# iostr912f register map
Registers are 32-bit, access not given, no defined reset value unless marked. A register's access mark holds for its fields unless they carry their own. Addresses are absolute; registers are grouped by the start of their names; [hi:lo] are bit positions; 'fields as' and 'values as' point back to an identical list.

## SSP1
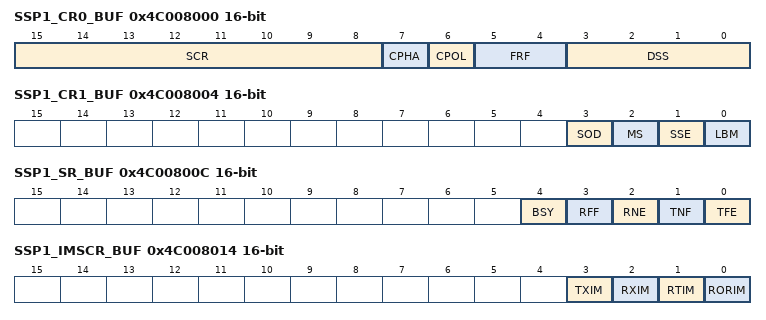
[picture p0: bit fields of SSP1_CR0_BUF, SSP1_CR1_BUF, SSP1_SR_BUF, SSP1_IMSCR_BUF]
0x4C008000 SSP1_CR0_BUF 16-bit
  [15:8] SCR, [7] CPHA, [6] CPOL, [5:4] FRF, [3:0] DSS
0x4C008004 SSP1_CR1_BUF 16-bit
  [3] SOD, [2] MS, [1] SSE, [0] LBM
0x4C008008 SSP1_DR_BUF 16-bit
0x4C00800C SSP1_SR_BUF 16-bit
  [4] BSY, [3] RFF, [2] RNE, [1] TNF, [0] TFE
0x4C008010 SSP1_PR_BUF 8-bit
0x4C008014 SSP1_IMSCR_BUF 16-bit
  [3] TXIM, [2] RXIM, [1] RTIM, [0] RORIM
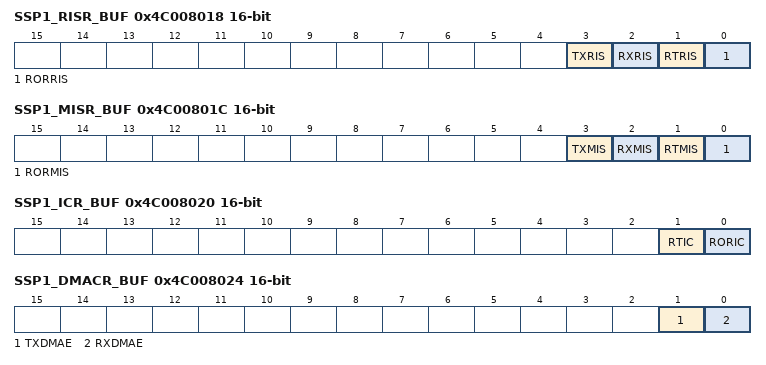
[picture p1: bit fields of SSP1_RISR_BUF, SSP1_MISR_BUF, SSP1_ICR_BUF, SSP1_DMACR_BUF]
0x4C008018 SSP1_RISR_BUF 16-bit
  [3] TXRIS, [2] RXRIS, [1] RTRIS, [0] RORRIS
0x4C00801C SSP1_MISR_BUF 16-bit
  [3] TXMIS, [2] RXMIS, [1] RTMIS, [0] RORMIS
0x4C008020 SSP1_ICR_BUF 16-bit
  [1] RTIC, [0] RORIC
0x4C008024 SSP1_DMACR_BUF 16-bit
  [1] TXDMAE, [0] RXDMAE
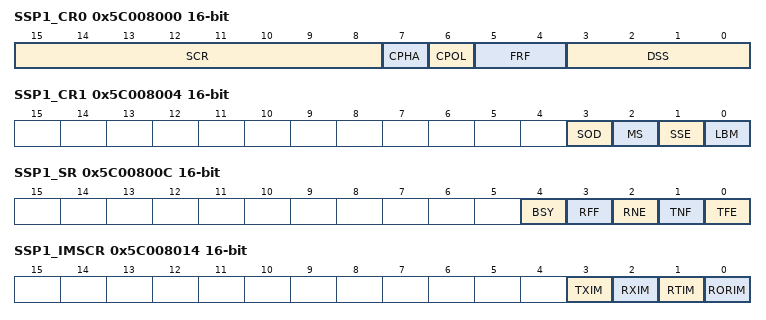
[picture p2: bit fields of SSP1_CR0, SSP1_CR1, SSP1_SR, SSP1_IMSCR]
0x5C008000 SSP1_CR0 16-bit
  [15:8] SCR, [7] CPHA, [6] CPOL, [5:4] FRF, [3:0] DSS
0x5C008004 SSP1_CR1 16-bit
  [3] SOD, [2] MS, [1] SSE, [0] LBM
0x5C008008 SSP1_DR 16-bit
0x5C00800C SSP1_SR 16-bit
  [4] BSY, [3] RFF, [2] RNE, [1] TNF, [0] TFE
0x5C008010 SSP1_PR 8-bit
0x5C008014 SSP1_IMSCR 16-bit
  [3] TXIM, [2] RXIM, [1] RTIM, [0] RORIM
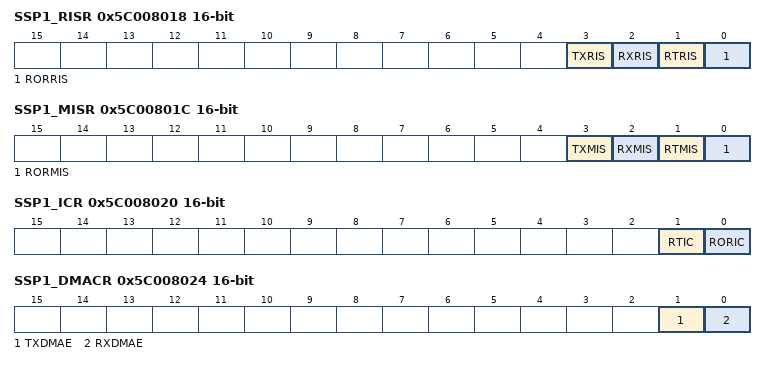
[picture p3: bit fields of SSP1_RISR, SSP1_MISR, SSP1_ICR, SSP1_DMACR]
0x5C008018 SSP1_RISR 16-bit
  [3] TXRIS, [2] RXRIS, [1] RTRIS, [0] RORRIS
0x5C00801C SSP1_MISR 16-bit
  [3] TXMIS, [2] RXMIS, [1] RTMIS, [0] RORMIS
0x5C008020 SSP1_ICR 16-bit
  [1] RTIC, [0] RORIC
0x5C008024 SSP1_DMACR 16-bit
  [1] TXDMAE, [0] RXDMAE

## UART0
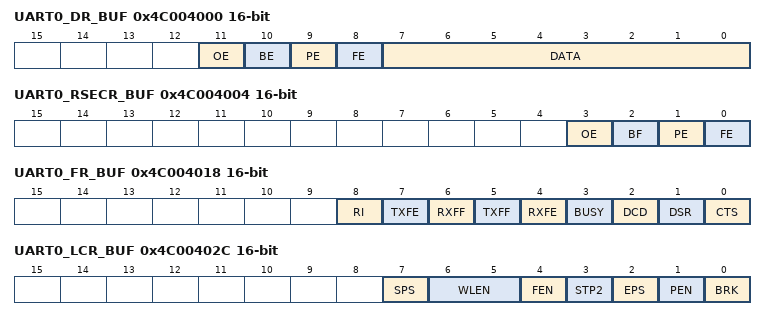
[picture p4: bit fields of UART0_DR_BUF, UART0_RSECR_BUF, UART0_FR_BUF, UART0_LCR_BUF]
0x4C004000 UART0_DR_BUF 16-bit
  [11] OE, [10] BE, [9] PE, [8] FE, [7:0] DATA
0x4C004004 UART0_RSECR_BUF 16-bit
  [3] OE, [2] BF, [1] PE, [0] FE
0x4C004018 UART0_FR_BUF 16-bit
  [8] RI, [7] TXFE, [6] RXFF, [5] TXFF, [4] RXFE, [3] BUSY, [2] DCD, [1] DSR, [0] CTS
0x4C004020 UART0_ILPR_BUF 8-bit
0x4C004024 UART0_IBRD_BUF 16-bit
0x4C004028 UART0_FBRD_BUF 16-bit
  [5:0] BAUD_DIVFRAC
0x4C00402C UART0_LCR_BUF 16-bit
  [7] SPS, [6:5] WLEN, [4] FEN, [3] STP2, [2] EPS, [1] PEN, [0] BRK
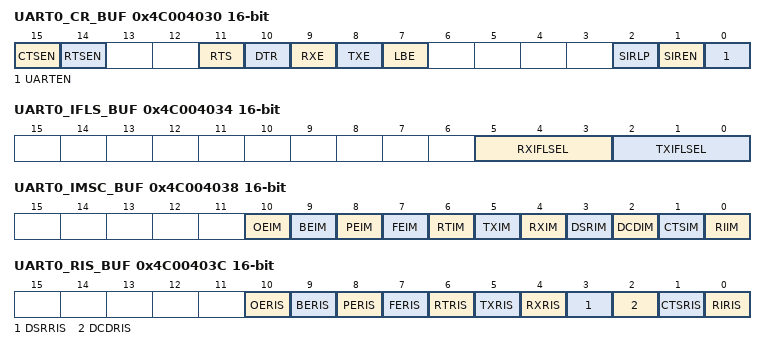
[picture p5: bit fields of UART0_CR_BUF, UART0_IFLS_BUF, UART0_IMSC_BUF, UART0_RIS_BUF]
0x4C004030 UART0_CR_BUF 16-bit
  [15] CTSEN, [14] RTSEN, [11] RTS, [10] DTR, [9] RXE, [8] TXE, [7] LBE, [2] SIRLP, [1] SIREN, [0] UARTEN
0x4C004034 UART0_IFLS_BUF 16-bit
  [5:3] RXIFLSEL, [2:0] TXIFLSEL
0x4C004038 UART0_IMSC_BUF 16-bit
  [10] OEIM, [9] BEIM, [8] PEIM, [7] FEIM, [6] RTIM, [5] TXIM, [4] RXIM, [3] DSRIM, [2] DCDIM, [1] CTSIM, [0] RIIM
0x4C00403C UART0_RIS_BUF 16-bit
  [10] OERIS, [9] BERIS, [8] PERIS, [7] FERIS, [6] RTRIS, [5] TXRIS, [4] RXRIS, [3] DSRRIS, [2] DCDRIS, [1] CTSRIS, [0] RIRIS
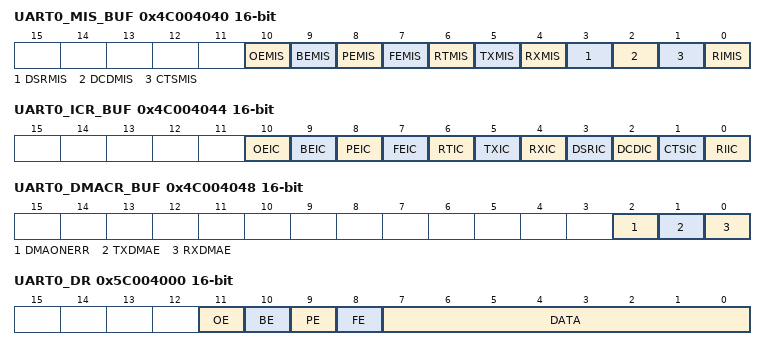
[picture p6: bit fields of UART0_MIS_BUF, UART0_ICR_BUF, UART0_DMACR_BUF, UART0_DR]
0x4C004040 UART0_MIS_BUF 16-bit
  [10] OEMIS, [9] BEMIS, [8] PEMIS, [7] FEMIS, [6] RTMIS, [5] TXMIS, [4] RXMIS, [3] DSRMIS, [2] DCDMIS, [1] CTSMIS, [0] RIMIS
0x4C004044 UART0_ICR_BUF 16-bit
  [10] OEIC, [9] BEIC, [8] PEIC, [7] FEIC, [6] RTIC, [5] TXIC, [4] RXIC, [3] DSRIC, [2] DCDIC, [1] CTSIC, [0] RIIC
0x4C004048 UART0_DMACR_BUF 16-bit
  [2] DMAONERR, [1] TXDMAE, [0] RXDMAE
0x5C004000 UART0_DR 16-bit
  [11] OE, [10] BE, [9] PE, [8] FE, [7:0] DATA
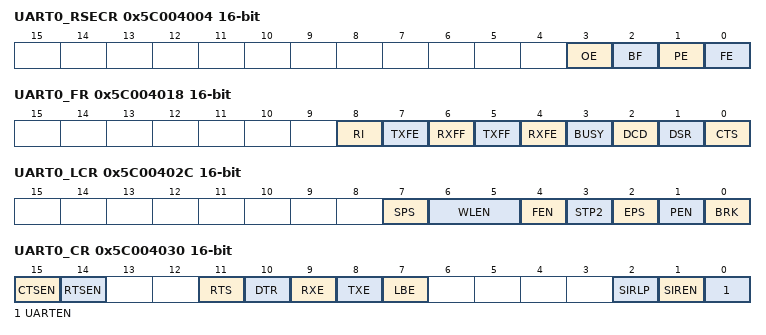
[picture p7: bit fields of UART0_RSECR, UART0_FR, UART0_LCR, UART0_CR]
0x5C004004 UART0_RSECR 16-bit
  [3] OE, [2] BF, [1] PE, [0] FE
0x5C004018 UART0_FR 16-bit
  fields as UART0_FR_BUF
0x5C004020 UART0_ILPR 8-bit
0x5C004024 UART0_IBRD 16-bit
0x5C004028 UART0_FBRD 16-bit
  [5:0] BAUD_DIVFRAC
0x5C00402C UART0_LCR 16-bit
  [7] SPS, [6:5] WLEN, [4] FEN, [3] STP2, [2] EPS, [1] PEN, [0] BRK
0x5C004030 UART0_CR 16-bit
  fields as UART0_CR_BUF
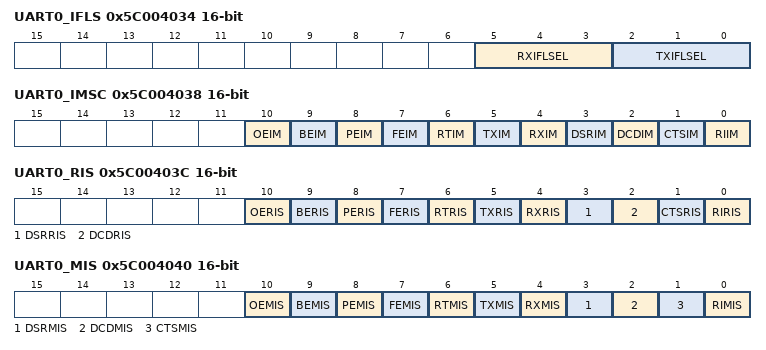
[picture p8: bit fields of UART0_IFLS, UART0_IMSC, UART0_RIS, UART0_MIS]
0x5C004034 UART0_IFLS 16-bit
  [5:3] RXIFLSEL, [2:0] TXIFLSEL
0x5C004038 UART0_IMSC 16-bit
  fields as UART0_IMSC_BUF
0x5C00403C UART0_RIS 16-bit
  fields as UART0_RIS_BUF
0x5C004040 UART0_MIS 16-bit
  fields as UART0_MIS_BUF
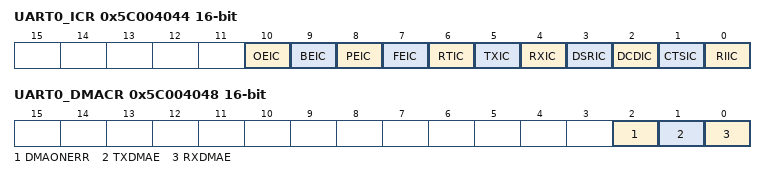
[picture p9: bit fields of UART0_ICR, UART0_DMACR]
0x5C004044 UART0_ICR 16-bit
  fields as UART0_ICR_BUF
0x5C004048 UART0_DMACR 16-bit
  [2] DMAONERR, [1] TXDMAE, [0] RXDMAE

## UART1
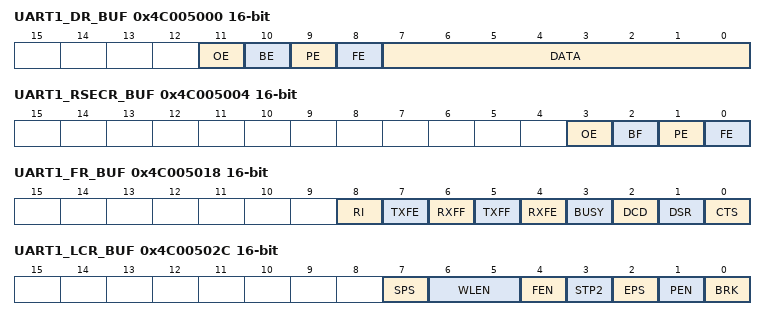
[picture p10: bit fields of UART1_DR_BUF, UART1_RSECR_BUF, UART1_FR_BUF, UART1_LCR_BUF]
0x4C005000 UART1_DR_BUF 16-bit
  [11] OE, [10] BE, [9] PE, [8] FE, [7:0] DATA
0x4C005004 UART1_RSECR_BUF 16-bit
  [3] OE, [2] BF, [1] PE, [0] FE
0x4C005018 UART1_FR_BUF 16-bit
  [8] RI, [7] TXFE, [6] RXFF, [5] TXFF, [4] RXFE, [3] BUSY, [2] DCD, [1] DSR, [0] CTS
0x4C005020 UART1_ILPR_BUF 8-bit
0x4C005024 UART1_IBRD_BUF 16-bit
0x4C005028 UART1_FBRD_BUF 16-bit
  [5:0] BAUD_DIVFRAC
0x4C00502C UART1_LCR_BUF 16-bit
  [7] SPS, [6:5] WLEN, [4] FEN, [3] STP2, [2] EPS, [1] PEN, [0] BRK
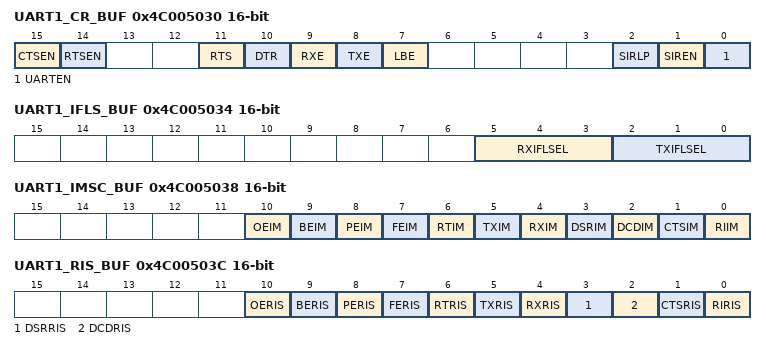
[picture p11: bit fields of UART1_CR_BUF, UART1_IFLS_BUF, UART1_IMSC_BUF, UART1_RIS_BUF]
0x4C005030 UART1_CR_BUF 16-bit
  [15] CTSEN, [14] RTSEN, [11] RTS, [10] DTR, [9] RXE, [8] TXE, [7] LBE, [2] SIRLP, [1] SIREN, [0] UARTEN
0x4C005034 UART1_IFLS_BUF 16-bit
  [5:3] RXIFLSEL, [2:0] TXIFLSEL
0x4C005038 UART1_IMSC_BUF 16-bit
  [10] OEIM, [9] BEIM, [8] PEIM, [7] FEIM, [6] RTIM, [5] TXIM, [4] RXIM, [3] DSRIM, [2] DCDIM, [1] CTSIM, [0] RIIM
0x4C00503C UART1_RIS_BUF 16-bit
  [10] OERIS, [9] BERIS, [8] PERIS, [7] FERIS, [6] RTRIS, [5] TXRIS, [4] RXRIS, [3] DSRRIS, [2] DCDRIS, [1] CTSRIS, [0] RIRIS
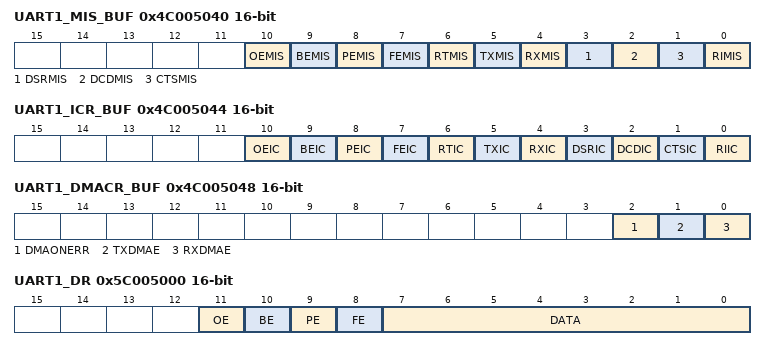
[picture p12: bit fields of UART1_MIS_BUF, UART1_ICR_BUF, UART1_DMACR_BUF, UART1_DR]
0x4C005040 UART1_MIS_BUF 16-bit
  [10] OEMIS, [9] BEMIS, [8] PEMIS, [7] FEMIS, [6] RTMIS, [5] TXMIS, [4] RXMIS, [3] DSRMIS, [2] DCDMIS, [1] CTSMIS, [0] RIMIS
0x4C005044 UART1_ICR_BUF 16-bit
  [10] OEIC, [9] BEIC, [8] PEIC, [7] FEIC, [6] RTIC, [5] TXIC, [4] RXIC, [3] DSRIC, [2] DCDIC, [1] CTSIC, [0] RIIC
0x4C005048 UART1_DMACR_BUF 16-bit
  [2] DMAONERR, [1] TXDMAE, [0] RXDMAE
0x5C005000 UART1_DR 16-bit
  [11] OE, [10] BE, [9] PE, [8] FE, [7:0] DATA
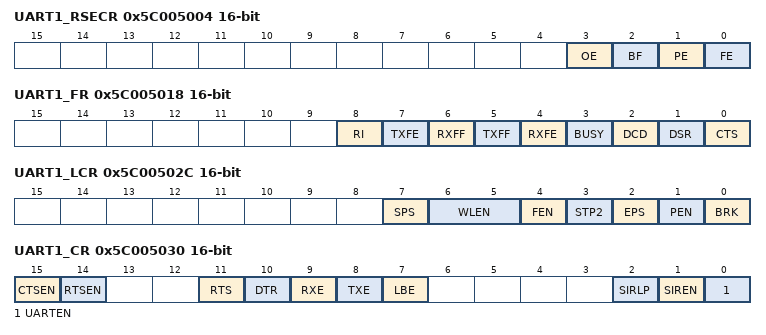
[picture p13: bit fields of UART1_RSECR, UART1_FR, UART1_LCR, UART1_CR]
0x5C005004 UART1_RSECR 16-bit
  [3] OE, [2] BF, [1] PE, [0] FE
0x5C005018 UART1_FR 16-bit
  fields as UART1_FR_BUF
0x5C005020 UART1_ILPR 8-bit
0x5C005024 UART1_IBRD 16-bit
0x5C005028 UART1_FBRD 16-bit
  [5:0] BAUD_DIVFRAC
0x5C00502C UART1_LCR 16-bit
  [7] SPS, [6:5] WLEN, [4] FEN, [3] STP2, [2] EPS, [1] PEN, [0] BRK
0x5C005030 UART1_CR 16-bit
  fields as UART1_CR_BUF
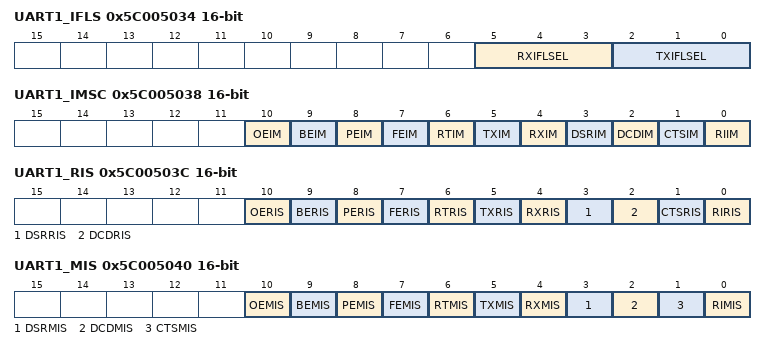
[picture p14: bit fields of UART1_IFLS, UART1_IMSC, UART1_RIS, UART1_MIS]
0x5C005034 UART1_IFLS 16-bit
  [5:3] RXIFLSEL, [2:0] TXIFLSEL
0x5C005038 UART1_IMSC 16-bit
  fields as UART1_IMSC_BUF
0x5C00503C UART1_RIS 16-bit
  fields as UART1_RIS_BUF
0x5C005040 UART1_MIS 16-bit
  fields as UART1_MIS_BUF
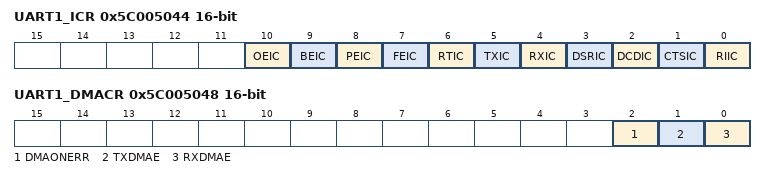
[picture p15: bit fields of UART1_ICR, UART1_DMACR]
0x5C005044 UART1_ICR 16-bit
  fields as UART1_ICR_BUF
0x5C005048 UART1_DMACR 16-bit
  [2] DMAONERR, [1] TXDMAE, [0] RXDMAE
